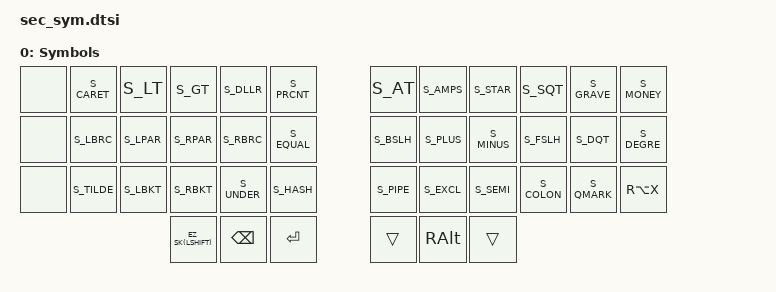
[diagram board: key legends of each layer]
#define EXTRA_LAYERS_START_INDEX (EXTRA_LAYERS_START_INDEX + 1)

/ {
  keymap {
    compatible = "zmk,keymap";

    sec_sym_layer: secundary_sym_layer {
      display-name = "Symbols";
      bindings = <
        &none  S_CARET S_LT    S_GT    S_DLLR  S_PRCNT       S_AT    S_AMPS  S_STAR  S_SQT   S_GRAVE  S_MONEY
        &none  S_LBRC  S_LPAR  S_RPAR  S_RBRC  S_EQUAL       S_BSLH  S_PLUS  S_MINUS S_FSLH  S_DQT    S_DEGRE
        &none  S_TILDE S_LBKT  S_RBKT  S_UNDER S_HASH        S_PIPE  S_EXCL  S_SEMI  S_COLON S_QMARK  &kp RA(X)
                    &EZ_SK(LSHIFT)  &kp BACKSPACE  &kp ENTER     &trans  &kp RALT  &trans
      >;
    };
  };
};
